VERSION "created by canmatrix"

NS_ :

BS_:

BU_: User ADM_PC_LL25 ADM_PC_BC25 ADM_PC_BP25 ADM_PC_BI25

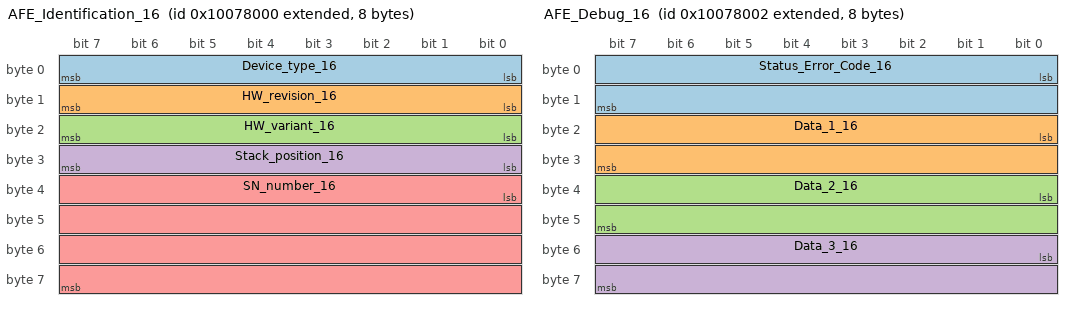
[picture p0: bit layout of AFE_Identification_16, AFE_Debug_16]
BO_ 2416410624 AFE_Identification_16: 8 ADM_PC_BP25
 SG_ Device_type_16 : 0|8@1+ (1,0) [0|255] "" Vector__XXX
 SG_ HW_revision_16 : 8|8@1+ (1,0) [0|255] "" Vector__XXX
 SG_ HW_variant_16 : 16|8@1+ (1,0) [0|255] "" Vector__XXX
 SG_ Stack_position_16 : 24|8@1+ (1,0) [0|255] "" Vector__XXX
 SG_ SN_number_16 : 32|32@1+ (1,0) [0|4294967295] "" Vector__XXX

BO_ 2416410625 AFE_FwInfo_16: 8 ADM_PC_BP25
 SG_ FW_info_mux_16 M : 56|8@1+ (1,0) [0|255] "" Vector__XXX
 SG_ FW_revision_0_16 m0 : 0|8@1+ (1,0) [0|255] "" Vector__XXX
 SG_ FW_revision_1_16 m0 : 8|8@1+ (1,0) [0|255] "" Vector__XXX
 SG_ FW_revision_2_16 m0 : 16|8@1+ (1,0) [0|255] "" Vector__XXX
 SG_ FW_revision_3_16 m0 : 24|8@1+ (1,0) [0|255] "" Vector__XXX
 SG_ FW_revision_4_16 m0 : 32|8@1+ (1,0) [0|255] "" Vector__XXX
 SG_ FW_revision_5_16 m0 : 40|8@1+ (1,0) [0|255] "" Vector__XXX
 SG_ FW_revision_6_16 m0 : 48|8@1+ (1,0) [0|255] "" Vector__XXX
 SG_ FW_revision_7_16 m1 : 0|8@1+ (1,0) [0|255] "" Vector__XXX
 SG_ FW_revision_8_16 m1 : 8|8@1+ (1,0) [0|255] "" Vector__XXX
 SG_ FW_revision_9_16 m1 : 16|8@1+ (1,0) [0|255] "" Vector__XXX
 SG_ FW_revision_10_16 m1 : 24|8@1+ (1,0) [0|255] "" Vector__XXX
 SG_ FW_revision_11_16 m1 : 32|8@1+ (1,0) [0|255] "" Vector__XXX
 SG_ FW_revision_12_16 m1 : 40|8@1+ (1,0) [0|255] "" Vector__XXX
 SG_ FW_revision_13_16 m1 : 48|8@1+ (1,0) [0|255] "" Vector__XXX
 SG_ FW_datecode_0_16 m2 : 0|8@1+ (1,0) [0|255] "" Vector__XXX
 SG_ FW_datecode_1_16 m2 : 8|8@1+ (1,0) [0|255] "" Vector__XXX
 SG_ FW_datecode_2_16 m2 : 16|8@1+ (1,0) [0|255] "" Vector__XXX
 SG_ FW_datecode_3_16 m2 : 24|8@1+ (1,0) [0|255] "" Vector__XXX
 SG_ FW_datecode_4_16 m2 : 32|8@1+ (1,0) [0|255] "" Vector__XXX
 SG_ FW_datecode_5_16 m2 : 40|8@1+ (1,0) [0|255] "" Vector__XXX
 SG_ FW_datecode_6_16 m2 : 48|8@1+ (1,0) [0|255] "" Vector__XXX
 SG_ FW_datecode_7_16 m3 : 0|8@1+ (1,0) [0|255] "" Vector__XXX
 SG_ FW_datecode_8_16 m3 : 8|8@1+ (1,0) [0|255] "" Vector__XXX
 SG_ FW_datecode_9_16 m3 : 16|8@1+ (1,0) [0|255] "" Vector__XXX
 SG_ FW_datecode_10_16 m3 : 24|8@1+ (1,0) [0|255] "" Vector__XXX
 SG_ FW_datecode_11_16 m3 : 32|8@1+ (1,0) [0|255] "" Vector__XXX
 SG_ FW_datecode_12_16 m3 : 40|8@1+ (1,0) [0|255] "" Vector__XXX
 SG_ FW_datecode_13_16 m3 : 48|8@1+ (1,0) [0|255] "" Vector__XXX

BO_ 2416410637 _AFE_Boot_FwInfo_16: 8 ADM_PC_BP25
 SG_ Boot_FW_info_mux_16 M : 56|8@1+ (1,0) [0|255] "" Vector__XXX
 SG_ FW_revision_0_16 m0 : 0|8@1+ (1,0) [0|255] "" Vector__XXX
 SG_ FW_revision_1_16 m0 : 8|8@1+ (1,0) [0|255] "" Vector__XXX
 SG_ FW_revision_2_16 m0 : 16|8@1+ (1,0) [0|255] "" Vector__XXX
 SG_ FW_revision_3_16 m0 : 24|8@1+ (1,0) [0|255] "" Vector__XXX
 SG_ FW_revision_4_16 m0 : 32|8@1+ (1,0) [0|255] "" Vector__XXX
 SG_ FW_revision_5_16 m0 : 40|8@1+ (1,0) [0|255] "" Vector__XXX
 SG_ FW_revision_6_16 m0 : 48|8@1+ (1,0) [0|255] "" Vector__XXX
 SG_ FW_revision_7_16 m1 : 0|8@1+ (1,0) [0|255] "" Vector__XXX
 SG_ FW_revision_8_16 m1 : 8|8@1+ (1,0) [0|255] "" Vector__XXX
 SG_ FW_revision_9_16 m1 : 16|8@1+ (1,0) [0|255] "" Vector__XXX
 SG_ FW_revision_10_16 m1 : 24|8@1+ (1,0) [0|255] "" Vector__XXX
 SG_ FW_revision_11_16 m1 : 32|8@1+ (1,0) [0|255] "" Vector__XXX
 SG_ FW_revision_12_16 m1 : 40|8@1+ (1,0) [0|255] "" Vector__XXX
 SG_ FW_revision_13_16 m1 : 48|8@1+ (1,0) [0|255] "" Vector__XXX
 SG_ FW_datecode_0_16 m2 : 0|8@1+ (1,0) [0|255] "" Vector__XXX
 SG_ FW_datecode_1_16 m2 : 8|8@1+ (1,0) [0|255] "" Vector__XXX
 SG_ FW_datecode_2_16 m2 : 16|8@1+ (1,0) [0|255] "" Vector__XXX
 SG_ FW_datecode_3_16 m2 : 24|8@1+ (1,0) [0|255] "" Vector__XXX
 SG_ FW_datecode_4_16 m2 : 32|8@1+ (1,0) [0|255] "" Vector__XXX
 SG_ FW_datecode_5_16 m2 : 40|8@1+ (1,0) [0|255] "" Vector__XXX
 SG_ FW_datecode_6_16 m2 : 48|8@1+ (1,0) [0|255] "" Vector__XXX
 SG_ FW_datecode_7_16 m3 : 0|8@1+ (1,0) [0|255] "" Vector__XXX
 SG_ FW_datecode_8_16 m3 : 8|8@1+ (1,0) [0|255] "" Vector__XXX
 SG_ FW_datecode_9_16 m3 : 16|8@1+ (1,0) [0|255] "" Vector__XXX
 SG_ FW_datecode_10_16 m3 : 24|8@1+ (1,0) [0|255] "" Vector__XXX
 SG_ FW_datecode_11_16 m3 : 32|8@1+ (1,0) [0|255] "" Vector__XXX
 SG_ FW_datecode_12_16 m3 : 40|8@1+ (1,0) [0|255] "" Vector__XXX
 SG_ FW_datecode_13_16 m3 : 48|8@1+ (1,0) [0|255] "" Vector__XXX

BO_ 2416410626 AFE_Debug_16: 8 ADM_PC_BP25
 SG_ Status_Error_Code_16 : 0|16@1+ (1,0) [0|65535] "" Vector__XXX
 SG_ Data_1_16 : 16|16@1+ (1,0) [0|65535] "" Vector__XXX
 SG_ Data_2_16 : 32|16@1+ (1,0) [0|65535] "" Vector__XXX
 SG_ Data_3_16 : 48|16@1+ (1,0) [0|65535] "" Vector__XXX

BO_ 2416410631 AFE_Status_16: 8 ADM_PC_BP25
 SG_ Running_16 : 0|1@1+ (1,0) [0|1] "" Vector__XXX
 SG_ PWM_16 : 1|1@1+ (1,0) [0|1] "" Vector__XXX
 SG_ Current_dc_loop_mode_16 : 2|1@1+ (1,0) [0|1] "" Vector__XXX
 SG_ Current_ac_loop_mode_16 : 3|1@1+ (1,0) [0|1] "" Vector__XXX
 SG_ Buck_16 : 5|1@1+ (1,0) [0|1] "" Vector__XXX
 SG_ Boost_16 : 6|1@1+ (1,0) [0|1] "" Vector__XXX
 SG_ Precharge_dc_buck_mode_16 : 7|1@1+ (1,0) [0|1] "" Vector__XXX
 SG_ Precharge_dc_boost_mode_16 : 8|1@1+ (1,0) [0|1] "" Vector__XXX
 SG_ Rectifier_3ph_16 : 9|1@1+ (1,0) [0|1] "" Vector__XXX
 SG_ Stack_mode_16 : 10|1@1+ (1,0) [0|1] "" Vector__XXX
 SG_ Master_16 : 11|1@1+ (1,0) [0|1] "" Vector__XXX
 SG_ Slave_16 : 12|1@1+ (1,0) [0|1] "" Vector__XXX
 SG_ Inverter_1ph_16 : 13|1@1+ (1,0) [0|1] "" Vector__XXX
 SG_ Boost_Neutral_16 : 14|1@1+ (1,0) [0|1] "" Vector__XXX
 SG_ Rectifier_1ph_16 : 15|1@1+ (1,0) [0|1] "" Vector__XXX
 SG_ Inverter_3ph_16 : 16|1@1+ (1,0) [0|1] "" Vector__XXX
 SG_ Ready_16 : 17|1@1+ (1,0) [0|1] "" Vector__XXX
 SG_ Inverter_1ph_Sync_16 : 18|1@1+ (1,0) [0|1] "" Vector__XXX
 SG_ Neutral_16 : 19|1@1+ (1,0) [0|1] "" Vector__XXX
 SG_ Rectifier_1ph_Buck_16 : 20|1@1+ (1,0) [0|1] "" Vector__XXX
 SG_ Inverter_1ph_Boost_16 : 21|1@1+ (1,0) [0|1] "" Vector__XXX
 SG_ Rectifier_distributed_16 : 22|1@1+ (1,0) [0|1] "" Vector__XXX
 SG_ MPPT_buck_16 : 23|1@1+ (1,0) [0|1] "" Vector__XXX
 SG_ MPPT_boost_16 : 24|1@1+ (1,0) [0|1] "" Vector__XXX
 SG_ Buck_2p_float_16 : 25|1@1+ (1,0) [0|1] "" Vector__XXX
 SG_ Inverter_1ph_Distributed_16 : 26|1@1+ (1,0) [0|1] "" Vector__XXX

BO_ 2416410630 AFE_Faults_16: 3 ADM_PC_BP25
 SG_ Protection_trip_internal_16 : 0|1@1+ (1,0) [0|1] "" Vector__XXX
 SG_ Protection_trip_external_16 : 1|1@1+ (1,0) [0|1] "" Vector__XXX
 SG_ Phase_U_overcurrent_16 : 2|1@1+ (1,0) [0|1] "" Vector__XXX
 SG_ Phase_U_overvoltage_16 : 3|1@1+ (1,0) [0|1] "" Vector__XXX
 SG_ Phase_U_undervoltage_16 : 4|1@1+ (1,0) [0|1] "" Vector__XXX
 SG_ Phase_V_overvoltage_16 : 5|1@1+ (1,0) [0|1] "" Vector__XXX
 SG_ Phase_V_undervoltage_16 : 6|1@1+ (1,0) [0|1] "" Vector__XXX
 SG_ Phase_V_overcurrent_16 : 7|1@1+ (1,0) [0|1] "" Vector__XXX
 SG_ Phase_W_overvoltage_16 : 8|1@1+ (1,0) [0|1] "" Vector__XXX
 SG_ Phase_W_undervoltage_16 : 9|1@1+ (1,0) [0|1] "" Vector__XXX
 SG_ Phase_W_overcurrent_16 : 10|1@1+ (1,0) [0|1] "" Vector__XXX
 SG_ DC_undervoltage_16 : 11|1@1+ (1,0) [0|1] "" Vector__XXX
 SG_ DC_overvoltage_16 : 12|1@1+ (1,0) [0|1] "" Vector__XXX
 SG_ MOSFET_overtemperature_16 : 13|1@1+ (1,0) [0|1] "" Vector__XXX
 SG_ Inductor_overtemperature_16 : 14|1@1+ (1,0) [0|1] "" Vector__XXX
 SG_ Keep_Alive_not_served_16 : 15|1@1+ (1,0) [0|1] "" Vector__XXX
 SG_ PLL_not_locked_16 : 16|1@1+ (1,0) [0|1] "" Vector__XXX
 SG_ NFO_16 : 20|1@1+ (1,0) [0|1] "" Vector__XXX
 SG_ Measurement_system_failure_16 : 21|1@1+ (1,0) [0|1] "" Vector__XXX
 SG_ EEPROM_failure_16 : 22|1@1+ (1,0) [0|1] "" Vector__XXX
 SG_ System_16 : 23|1@1+ (1,0) [0|1] "" Vector__XXX

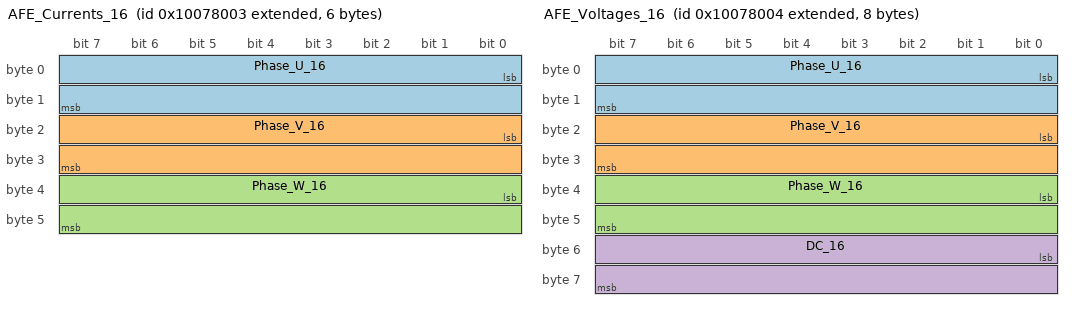
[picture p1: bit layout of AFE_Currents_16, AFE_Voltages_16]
BO_ 2416410627 AFE_Currents_16: 6 ADM_PC_BP25
 SG_ Phase_U_16 : 0|16@1- (0.01,0) [-327.68|327.67] "A" Vector__XXX
 SG_ Phase_V_16 : 16|16@1- (0.01,0) [-327.68|327.67] "A" Vector__XXX
 SG_ Phase_W_16 : 32|16@1- (0.01,0) [-327.68|327.67] "A" Vector__XXX

BO_ 2416410640 AFE_DC_Bus_current_16: 2 ADM_PC_BP25
 SG_ Bus_current_16 : 0|16@1- (0.01,0) [-327.68|327.67] "A" Vector__XXX

BO_ 2416410638 _AFE_Broadcast_16: 8 ADM_PC_BP25
 SG_ Diagnostics_Index_16 M : 56|8@1+ (1,0) [0|255] "" Vector__XXX
 SG_ Phase_U_16 m1 : 8|16@1- (0.01,0) [-327.68|327.67] "A" ADM_PC_BP25
 SG_ Phase_V_16 m1 : 24|16@1- (0.01,0) [-327.68|327.67] "A" ADM_PC_BP25
 SG_ Phase_W_16 m1 : 40|16@1- (0.01,0) [-327.68|327.67] "A" ADM_PC_BP25
 SG_ Stack_position_16 : 0|5@1+ (1,0) [0|31] "" ADM_PC_BP25
 SG_ Group_ID_16 : 5|3@1+ (1,0) [0|7] "" ADM_PC_BP25

BO_ 2416410628 AFE_Voltages_16: 8 ADM_PC_BP25
 SG_ Phase_U_16 : 0|16@1- (0.1,0) [-3276.8|3276.7] "V" Vector__XXX
 SG_ Phase_V_16 : 16|16@1- (0.1,0) [-3276.8|3276.7] "V" Vector__XXX
 SG_ Phase_W_16 : 32|16@1- (0.1,0) [-3276.8|3276.7] "V" Vector__XXX
 SG_ DC_16 : 48|16@1- (0.1,0) [-3276.8|3276.7] "V" Vector__XXX

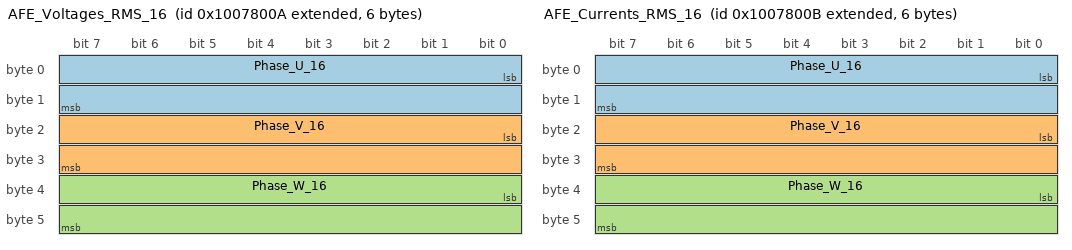
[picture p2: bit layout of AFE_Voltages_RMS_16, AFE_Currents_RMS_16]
BO_ 2416410634 AFE_Voltages_RMS_16: 6 ADM_PC_BP25
 SG_ Phase_U_16 : 0|16@1+ (0.1,0) [0|6553.5] "V" Vector__XXX
 SG_ Phase_V_16 : 16|16@1+ (0.1,0) [0|6553.5] "V" Vector__XXX
 SG_ Phase_W_16 : 32|16@1+ (0.1,0) [0|6553.5] "V" Vector__XXX

BO_ 2416410635 AFE_Currents_RMS_16: 6 ADM_PC_BP25
 SG_ Phase_U_16 : 0|16@1+ (0.01,0) [0.00|655.35] "A" Vector__XXX
 SG_ Phase_V_16 : 16|16@1+ (0.01,0) [0.00|655.35] "A" Vector__XXX
 SG_ Phase_W_16 : 32|16@1+ (0.01,0) [0.00|655.35] "A" Vector__XXX

BO_ 2416410636 AFE_Mains_16: 4 ADM_PC_BP25
 SG_ Frequency_16 : 0|16@1+ (0.01,0) [0.00|655.35] "Hz" Vector__XXX
 SG_ Phase_16 : 16|16@1- (0.1,0) [-3276.8|3276.7] "Deg." Vector__XXX

BO_ 2416410629 AFE_Temperatures_16: 4 ADM_PC_BP25
 SG_ Temp_Bridge_16 : 0|16@1- (0.01,0) [-327.68|327.67] "°C" Vector__XXX
 SG_ Temp_Inductors_16 : 16|16@1- (0.01,0) [-327.68|327.67] "°C" Vector__XXX

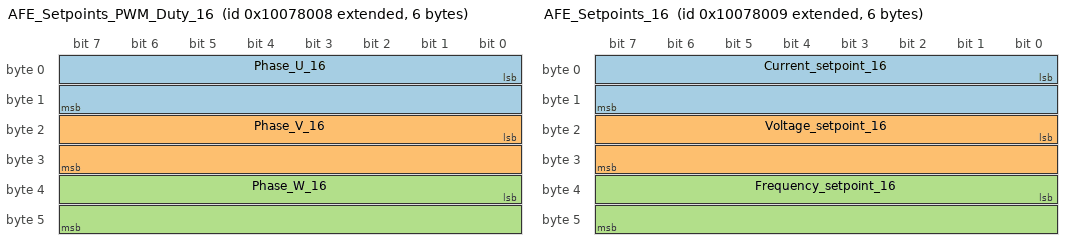
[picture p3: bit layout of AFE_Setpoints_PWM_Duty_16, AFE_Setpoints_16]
BO_ 2416410632 AFE_Setpoints_PWM_Duty_16: 6 ADM_PC_BP25
 SG_ Phase_U_16 : 0|16@1+ (0.001525902,0) [0E-009|99.999987570] "%" Vector__XXX
 SG_ Phase_V_16 : 16|16@1+ (0.001525902,0) [0E-009|99.999987570] "%" Vector__XXX
 SG_ Phase_W_16 : 32|16@1+ (0.001525902,0) [0E-009|99.999987570] "%" Vector__XXX

BO_ 2416410633 AFE_Setpoints_16: 6 ADM_PC_BP25
 SG_ Current_setpoint_16 : 0|16@1- (0.01,0) [-327.68|327.67] "A" Vector__XXX
 SG_ Voltage_setpoint_16 : 16|16@1+ (0.1,0) [0|6553.5] "V" Vector__XXX
 SG_ Frequency_setpoint_16 : 32|16@1+ (0.01,0) [0.00|655.35] "Hz" Vector__XXX

BO_ 2416377952 AFE_Keep_Alive_16: 1 User
 SG_ Keep_Alive_Enable_16 : 0|1@1+ (1,0) [0|1] "" ADM_PC_BP25

BO_ 2416377920 AFE_Mode_Control_16: 8 User
 SG_ Converter_ON_16 : 0|1@1+ (1,0) [0|1] "" ADM_PC_BP25
 SG_ PWM_ON_16 : 1|1@1+ (1,0) [0|1] "" ADM_PC_BP25
 SG_ DC_Current_feedback_ON_16 : 2|1@1+ (1,0) [0|1] "" ADM_PC_BP25
 SG_ AC_Current_feedback_ON_16 : 3|1@1+ (1,0) [0|1] "" ADM_PC_BP25
 SG_ Buck_ON_16 : 5|1@1+ (1,0) [0|1] "" ADM_PC_BP25
 SG_ Boost_ON_16 : 6|1@1+ (1,0) [0|1] "" ADM_PC_BP25
 SG_ Rectifier_3ph_ON_16 : 9|1@1+ (1,0) [0|1] "" ADM_PC_BP25
 SG_ Inverter_1ph_ON_16 : 10|1@1+ (1,0) [0|1] "" ADM_PC_BP25
 SG_ Rectifier_1ph_ON_16 : 11|1@1+ (1,0) [0|1] "" ADM_PC_BP25
 SG_ Boost_Neutral_ON_16 : 12|1@1+ (1,0) [0|1] "" ADM_PC_BP25
 SG_ Inverter_3ph_ON_16 : 13|1@1+ (1,0) [0|1] "" ADM_PC_BP25
 SG_ Inverter_1ph_Sync_ON_16 : 14|1@1+ (1,0) [0|1] "" ADM_PC_BP25
 SG_ Neutral_ON_16 : 15|1@1+ (1,0) [0|1] "" ADM_PC_BP25
 SG_ Rectifier_1ph_Buck_ON_16 : 16|1@1+ (1,0) [0|1] "" ADM_PC_BP25
 SG_ Inverter_1ph_Boost_ON_16 : 17|1@1+ (1,0) [0|1] "" ADM_PC_BP25
 SG_ Rectifier_Distributed_ON_16 : 18|1@1+ (1,0) [0|1] "" ADM_PC_BP25
 SG_ MPPT_buck_ON_16 : 19|1@1+ (1,0) [0|1] "" ADM_PC_BP25
 SG_ MPPT_boost_ON_16 : 20|1@1+ (1,0) [0|1] "" ADM_PC_BP25
 SG_ Buck_2p_float_ON_16 : 21|1@1+ (1,0) [0|1] "" ADM_PC_BP25
 SG_ Inverter_1ph_Distributed_ON_16 : 22|1@1+ (1,0) [0|1] "" ADM_PC_BP25

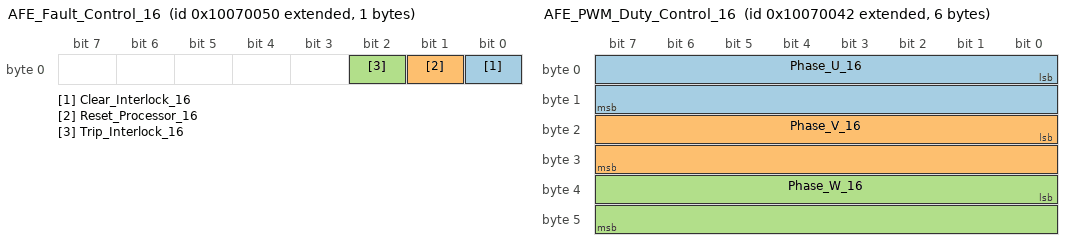
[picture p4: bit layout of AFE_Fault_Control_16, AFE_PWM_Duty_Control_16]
BO_ 2416377936 AFE_Fault_Control_16: 1 User
 SG_ Clear_Interlock_16 : 0|1@1+ (1,0) [0|1] "" ADM_PC_BP25
 SG_ Reset_Processor_16 : 1|1@1+ (1,0) [0|1] "" ADM_PC_BP25
 SG_ Trip_Interlock_16 : 2|1@1+ (1,0) [0|1] "" ADM_PC_BP25

BO_ 2416377921 AFE_Reactive_Current_Setpoint_Co: 2 User
 SG_ Reactive_current_setpoint_16 : 0|16@1- (0.01,0) [-150|150] "A" ADM_PC_BP25

BO_ 2416377922 AFE_PWM_Duty_Control_16: 6 User
 SG_ Phase_U_16 : 0|16@1+ (0.001525902,0) [0E-009|99.999987570] "%" ADM_PC_BP25
 SG_ Phase_V_16 : 16|16@1+ (0.001525902,0) [0E-009|99.999987570] "%" ADM_PC_BP25
 SG_ Phase_W_16 : 32|16@1+ (0.001525902,0) [0E-009|99.999987570] "%" ADM_PC_BP25

BO_ 2416377923 AFE_Current_Setpoint_Control_16: 2 User
 SG_ Current_setpoint_16 : 0|16@1- (0.01,0) [-150|150] "A" ADM_PC_BP25

BO_ 2416377924 AFE_Voltage_Setpoint_Control_16: 2 User
 SG_ Voltage_setpoint_16 : 0|16@1+ (0.1,0) [0|1500] "V" ADM_PC_BP25

BO_ 2416377928 AFE_Frequency_Setpoint_Control_1: 2 User
 SG_ Frequency_setpoint_16 : 0|16@1+ (0.01,0) [40|70] "Hz" ADM_PC_BP25

BO_ 2416377929 AFE_Phase_Setpoint_Control_16: 2 User
 SG_ Phase_setpoint_16 : 0|16@1+ (1,0) [0|360] "deg" ADM_PC_BP25

BO_ 2416377968 AFE_Rectifier_Setpoint_Control_1: 8 User
 SG_ Voltage_setpoint_2_16 : 0|16@1+ (0.1,0) [0|1500] "V" ADM_PC_BP25
 SG_ Current_setpoint_2_16 : 16|16@1- (0.01,0) [-150|150] "A" ADM_PC_BP25

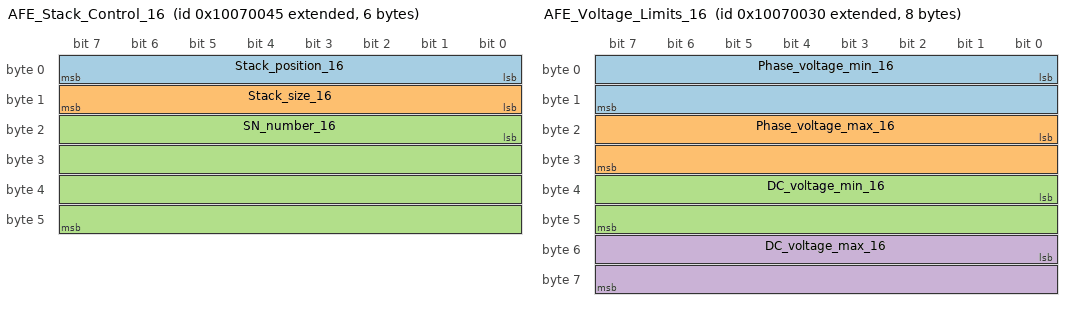
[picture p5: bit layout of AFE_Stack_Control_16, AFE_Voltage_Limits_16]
BO_ 2416377925 AFE_Stack_Control_16: 6 User
 SG_ Stack_position_16 : 0|8@1+ (1,0) [0|255] "" ADM_PC_BP25
 SG_ Stack_size_16 : 8|8@1+ (1,0) [0|255] "" ADM_PC_BP25
 SG_ SN_number_16 : 16|32@1+ (1,0) [0|4294967295] "" ADM_PC_BP25

BO_ 2416377904 AFE_Voltage_Limits_16: 8 User
 SG_ Phase_voltage_min_16 : 0|16@1- (0.1,0) [0|3276.7] "V" ADM_PC_BP25
 SG_ Phase_voltage_max_16 : 16|16@1- (0.1,0) [-3276.8|850] "V" ADM_PC_BP25
 SG_ DC_voltage_min_16 : 32|16@1- (0.1,0) [0|3276.7] "V" ADM_PC_BP25
 SG_ DC_voltage_max_16 : 48|16@1- (0.1,0) [-3276.8|850] "V" ADM_PC_BP25

BO_ 2416377905 AFE_Current_Limits_16: 4 User
 SG_ Phase_current_min_16 : 0|16@1- (0.01,0) [-60|60] "A" ADM_PC_BP25
 SG_ Phase_current_max_16 : 16|16@1- (0.01,0) [-60|60] "A" ADM_PC_BP25

BO_ 2416377932 AFE_Group_Control_16: 1 User
 SG_ Group_ID_16 : 0|8@1+ (1,0) [0|255] "" ADM_PC_BP25

BO_ 2416410639 AFE_Group_Info_16: 1 ADM_PC_BP25
 SG_ Group_ID_16 : 0|8@1+ (1,0) [0|255] "" Vector__XXX

BO_ 2416377953 AFE_System_Flags_Control_16: 8 User
 SG_ Factory_mode_16 : 0|1@1+ (1,0) [0|1] "" ADM_PC_BP25
 SG_ Silent_CAN_mode_16 : 1|1@1+ (1,0) [0|1] "" ADM_PC_BP25

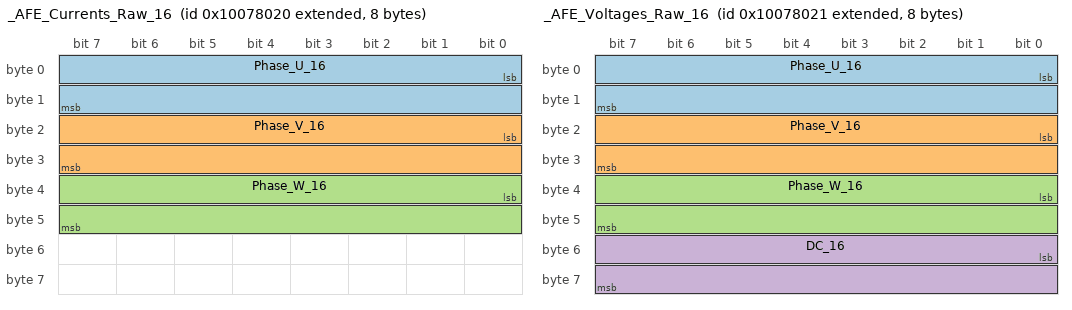
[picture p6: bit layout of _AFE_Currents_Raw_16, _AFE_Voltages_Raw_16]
BO_ 2416410656 _AFE_Currents_Raw_16: 8 ADM_PC_BP25
 SG_ Phase_U_16 : 0|16@1- (1,0) [-32768|32767] "" Vector__XXX
 SG_ Phase_V_16 : 16|16@1- (1,0) [-32768|32767] "" Vector__XXX
 SG_ Phase_W_16 : 32|16@1- (1,0) [-32768|32767] "" Vector__XXX

BO_ 2416410657 _AFE_Voltages_Raw_16: 8 ADM_PC_BP25
 SG_ Phase_U_16 : 0|16@1- (1,0) [-32768|32767] "" Vector__XXX
 SG_ Phase_V_16 : 16|16@1- (1,0) [-32768|32767] "" Vector__XXX
 SG_ Phase_W_16 : 32|16@1- (1,0) [-32768|32767] "" Vector__XXX
 SG_ DC_16 : 48|16@1- (1,0) [-32768|32767] "" Vector__XXX

BO_ 2416377930 _AFE_ADC_Calibration_Mode_16: 1 User
 SG_ Calibration_Index_16 M : 2|5@1+ (1,0) [0|31] "" Vector__XXX
 SG_ Current_U_16 m1 : 0|2@1+ (1,0) [0|3] "" ADM_PC_BP25
 SG_ Current_V_16 m2 : 0|2@1+ (1,0) [0|3] "" ADM_PC_BP25
 SG_ Current_W_16 m3 : 0|2@1+ (1,0) [0|3] "" ADM_PC_BP25
 SG_ Voltage_U_16 m4 : 0|2@1+ (1,0) [0|3] "" ADM_PC_BP25
 SG_ Voltage_V_16 m5 : 0|2@1+ (1,0) [0|3] "" ADM_PC_BP25
 SG_ Voltage_W_16 m6 : 0|2@1+ (1,0) [0|3] "" ADM_PC_BP25
 SG_ Voltage_DC_16 m7 : 0|2@1+ (1,0) [0|3] "" ADM_PC_BP25
 SG_ start_16 : 7|1@1+ (1,0) [0|1] "" ADM_PC_BP25

BO_ 2416377931 _AFE_ADC_Calibration_Setpoint_16: 3 User
 SG_ Calibration_Index_16 M : 16|5@1+ (1,0) [0|31] "" Vector__XXX
 SG_ Current_U_16 m1 : 0|16@1- (0.01,0) [-100|100] "A" ADM_PC_BP25
 SG_ Current_V_16 m2 : 0|16@1- (0.01,0) [-100|100] "A" ADM_PC_BP25
 SG_ Current_W_16 m3 : 0|16@1- (0.01,0) [-100|100] "A" ADM_PC_BP25
 SG_ Voltage_U_16 m4 : 0|16@1+ (0.1,0) [0|1500] "V" ADM_PC_BP25
 SG_ Voltage_V_16 m5 : 0|16@1+ (0.1,0) [0|1500] "V" ADM_PC_BP25
 SG_ Voltage_W_16 m6 : 0|16@1+ (0.1,0) [0|1500] "V" ADM_PC_BP25
 SG_ Voltage_DC_16 m7 : 0|16@1+ (0.1,0) [0|1500] "V" ADM_PC_BP25
 SG_ point_16 : 21|3@1+ (1,0) [0|7] "" ADM_PC_BP25

BO_ 2416377926 _AFE_Calibration_Offset_Update_1: 6 User
 SG_ Calibration_Index_16 M : 16|16@1+ (1,0) [0|65535] "" Vector__XXX
 SG_ Current_U_16 m0 : 0|16@1- (1,0) [-32768|32767] "ADC Counts" ADM_PC_BP25
 SG_ Current_V_16 m1 : 0|16@1- (1,0) [-32768|32767] "ADC Counts" ADM_PC_BP25
 SG_ Current_W_16 m2 : 0|16@1- (1,0) [-32768|32767] "ADC Counts" ADM_PC_BP25
 SG_ Voltage_U_16 m3 : 0|16@1- (1,0) [-32768|32767] "ADC Counts" ADM_PC_BP25
 SG_ Voltage_V_16 m4 : 0|16@1- (1,0) [-32768|32767] "ADC Counts" ADM_PC_BP25
 SG_ Voltage_W_16 m5 : 0|16@1- (1,0) [-32768|32767] "ADC Counts" ADM_PC_BP25
 SG_ Voltage_DC_16 m6 : 0|16@1- (1,0) [-32768|32767] "ADC Counts" ADM_PC_BP25
 SG_ CRC_16 : 32|16@1+ (1,0) [0|65535] "-" ADM_PC_BP25

BO_ 2416377927 _AFE_Calibration_Scale_Update_16: 6 User
 SG_ Calibration_Index_16 M : 16|16@1+ (1,0) [0|65535] "" Vector__XXX
 SG_ Current_U_16 m0 : 0|16@1- (0.0000152587890625,0) [-0.5000000000000000|0.4999847412109375] "scale = 1.0 + value" ADM_PC_BP25
 SG_ Current_V_16 m1 : 0|16@1- (0.0000152587890625,0) [-0.5000000000000000|0.4999847412109375] "scale = 1.0 + value" ADM_PC_BP25
 SG_ Current_W_16 m2 : 0|16@1- (0.0000152587890625,0) [-0.5000000000000000|0.4999847412109375] "scale = 1.0 + value" ADM_PC_BP25
 SG_ Voltage_U_16 m3 : 0|16@1- (0.0000152587890625,0) [-0.5000000000000000|0.4999847412109375] "scale = 1.0 + value" ADM_PC_BP25
 SG_ Voltage_V_16 m4 : 0|16@1- (0.0000152587890625,0) [-0.5000000000000000|0.4999847412109375] "scale = 1.0 + value" ADM_PC_BP25
 SG_ Voltage_W_16 m5 : 0|16@1- (0.0000152587890625,0) [-0.5000000000000000|0.4999847412109375] "scale = 1.0 + value" ADM_PC_BP25
 SG_ Voltage_DC_16 m6 : 0|16@1- (0.0000152587890625,0) [-0.5000000000000000|0.4999847412109375] "scale = 1.0 + value" ADM_PC_BP25
 SG_ CRC_16 : 32|16@1+ (1,0) [0|65535] "-" ADM_PC_BP25

BO_ 2416410705 _AFE_Calibration_Adc_Scale_16: 6 ADM_PC_BP25
 SG_ Adc_Index_16 M : 32|16@1+ (1,0) [0|65535] "" Vector__XXX
 SG_ Current_U_16 m0 : 0|32@1+ (1,0) [0|4294967295] "1 / adc_bins" User
 SG_ Current_V_16 m1 : 0|32@1+ (1,0) [0|4294967295] "1 / adc_bins" User
 SG_ Current_W_16 m2 : 0|32@1+ (1,0) [0|4294967295] "1 / adc_bins" User
 SG_ Voltage_U_16 m3 : 0|32@1+ (1,0) [0|4294967295] "1 / adc_bins" User
 SG_ Voltage_V_16 m4 : 0|32@1+ (1,0) [0|4294967295] "1 / adc_bins" User
 SG_ Voltage_W_16 m5 : 0|32@1+ (1,0) [0|4294967295] "1 / adc_bins" User
 SG_ Voltage_DC_16 m6 : 0|32@1+ (1,0) [0|4294967295] "1 / adc_bins" User

BO_ 2416410706 _AFE_Calibration_Adc_Fs_16: 6 ADM_PC_BP25
 SG_ Adc_Index_16 M : 32|16@1+ (1,0) [0|65535] "" Vector__XXX
 SG_ Current_U_16 m0 : 0|32@1+ (1,0) [0|4294967295] "Fullscale" User
 SG_ Current_V_16 m1 : 0|32@1+ (1,0) [0|4294967295] "Fullscale" User
 SG_ Current_W_16 m2 : 0|32@1+ (1,0) [0|4294967295] "Fullscale" User
 SG_ Voltage_U_16 m3 : 0|32@1+ (1,0) [0|4294967295] "Fullscale" User
 SG_ Voltage_V_16 m4 : 0|32@1+ (1,0) [0|4294967295] "Fullscale" User
 SG_ Voltage_W_16 m5 : 0|32@1+ (1,0) [0|4294967295] "Fullscale" User
 SG_ Voltage_DC_16 m6 : 0|32@1+ (1,0) [0|4294967295] "Fullscale" User

BO_ 2416410707 _AFE_Calibration_Adc_Offset_16: 4 ADM_PC_BP25
 SG_ Adc_Index_16 M : 16|16@1+ (1,0) [0|65535] "" Vector__XXX
 SG_ Current_U_16 m0 : 0|16@1- (1,0) [-32768|32767] "-" User
 SG_ Current_V_16 m1 : 0|16@1- (1,0) [-32768|32767] "-" User
 SG_ Current_W_16 m2 : 0|16@1- (1,0) [-32768|32767] "-" User
 SG_ Voltage_U_16 m3 : 0|16@1- (1,0) [-32768|32767] "-" User
 SG_ Voltage_V_16 m4 : 0|16@1- (1,0) [-32768|32767] "-" User
 SG_ Voltage_W_16 m5 : 0|16@1- (1,0) [-32768|32767] "-" User
 SG_ Voltage_DC_16 m6 : 0|16@1- (1,0) [-32768|32767] "-" User

BO_ 2416410708 _AFE_Calibration_Adc_Gain_16: 4 ADM_PC_BP25
 SG_ Adc_Index_16 M : 16|16@1+ (1,0) [0|65535] "" Vector__XXX
 SG_ Current_U_16 m0 : 0|16@1- (1,0) [-32768|32767] "-" User
 SG_ Current_V_16 m1 : 0|16@1- (1,0) [-32768|32767] "-" User
 SG_ Current_W_16 m2 : 0|16@1- (1,0) [-32768|32767] "-" User
 SG_ Voltage_U_16 m3 : 0|16@1- (1,0) [-32768|32767] "-" User
 SG_ Voltage_V_16 m4 : 0|16@1- (1,0) [-32768|32767] "-" User
 SG_ Voltage_W_16 m5 : 0|16@1- (1,0) [-32768|32767] "-" User
 SG_ Voltage_DC_16 m6 : 0|16@1- (1,0) [-32768|32767] "-" User

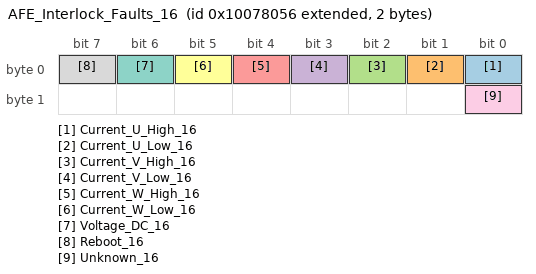
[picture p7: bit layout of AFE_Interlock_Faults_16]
BO_ 2416410710 AFE_Interlock_Faults_16: 2 ADM_PC_BP25
 SG_ Current_U_High_16 : 0|1@1+ (1,0) [0|1] "" Vector__XXX
 SG_ Current_U_Low_16 : 1|1@1+ (1,0) [0|1] "" Vector__XXX
 SG_ Current_V_High_16 : 2|1@1+ (1,0) [0|1] "" Vector__XXX
 SG_ Current_V_Low_16 : 3|1@1+ (1,0) [0|1] "" Vector__XXX
 SG_ Current_W_High_16 : 4|1@1+ (1,0) [0|1] "" Vector__XXX
 SG_ Current_W_Low_16 : 5|1@1+ (1,0) [0|1] "" Vector__XXX
 SG_ Voltage_DC_16 : 6|1@1+ (1,0) [0|1] "" Vector__XXX
 SG_ Reboot_16 : 7|1@1+ (1,0) [0|1] "" Vector__XXX
 SG_ Unknown_16 : 8|1@1+ (1,0) [0|1] "" Vector__XXX

BO_TX_BU_ 2416377920 : User,ADM_PC_LL25,ADM_PC_BC25,ADM_PC_BI25;
BO_TX_BU_ 2416377923 : User,ADM_PC_LL25,ADM_PC_BC25,ADM_PC_BI25;
BO_TX_BU_ 2416377924 : User,ADM_PC_LL25,ADM_PC_BC25,ADM_PC_BI25;
CM_ BO_ 2416410624  "Identification of the device";
CM_ BO_ 2416410625  "Git revision of the DSP firmware";
CM_ BO_ 2416410637  "Git revision of the bootloader firmware.";
CM_ BO_ 2416410626  "Values for debugging of HW/SW problems";
CM_ BO_ 2416410631  "Status bitfield";
CM_ BO_ 2416410630  "Fault bitfield";
CM_ BO_ 2416410627  "Current of phases U, V, W";
CM_ BO_ 2416410640  "Current of of the DC Bus";
CM_ BO_ 2416410638  "All AFEs will listen to this message";
CM_ BO_ 2416410635  "RMS Current of phases U, V, W";
CM_ BO_ 2416410636  "Three-Phase mains health (frequency, phase...)";
CM_ BO_ 2416410629  "Readouts of the module temperature sensors";
CM_ BO_ 2416410632  "Setpoints";
CM_ BO_ 2416410633  "Setpoints";
CM_ BO_ 2416377952  "Keep alive ping message. ";
CM_ BO_ 2416377920  "Operation Mode control: sets the converter operation mode";
CM_ BO_ 2416377936  "Fault Control: actions to clear faults and reset the system";
CM_ BO_ 2416377921  "Reactive power setpoint control.";
CM_ BO_ 2416377922  "PWM duty cycle control";
CM_ BO_ 2416377923  "Current setpoint control";
CM_ BO_ 2416377924  "Voltage setpoint control";
CM_ BO_ 2416377928  "Frequency setpoint control";
CM_ BO_ 2416377929  "Phase setpoint control";
CM_ BO_ 2416377968  "Additional voltage and current setpoints in single-phase rectifier and inverter control modes.";
CM_ BO_ 2416377925  "PFC stack control";
CM_ BO_ 2416377904  "Set the input and output voltage limits (minimum and maximum)";
CM_ BO_ 2416377905  "Set the output current limits (mminimum and maximum)";
CM_ BO_ 2416377932  "Set the Group ID of the device";
CM_ BO_ 2416410639  "Contains the Group ID of the device";
CM_ BO_ 2416377953  "Control the system flags";
CM_ BO_ 2416410656  "Current of phases A and B";
CM_ BO_ 2416410657  "Current of phases A and B";
CM_ BO_ 2416377930  "Automatic ADC calibration.";
CM_ BO_ 2416377931  "Setpoint for automatic ADC calibration.";
CM_ BO_ 2416377926  "Update of the calibration table for offsets.";
CM_ BO_ 2416377927  "Update of the calibration table for scales.";
CM_ BO_ 2416410705  "
                Adc scale (resolution) value of readouts.
            ";
CM_ BO_ 2416410706  "
                Adc fullscale value of readouts.
            ";
CM_ BO_ 2416410707  "
                Readout of ADC calibration data (offset) from EEPROM.
            ";
CM_ BO_ 2416410708  "
                Readout of ADC calibration data (gain) from EEPROM.
            ";
CM_ BO_ 2416410710  "Fault bitfield";

CM_ SG_ 2416410624 Device_type_16 "The device identification field, uniquely identifies the sender in the network";
CM_ SG_ 2416410624 HW_revision_16 "The hardware revision number";
CM_ SG_ 2416410624 HW_variant_16 "The DSP firmware revision number";
CM_ SG_ 2416410624 Stack_position_16 "Position of the module within the stack";
CM_ SG_ 2416410624 SN_number_16 "Unique module serial number";
CM_ SG_ 2416410625 FW_revision_0_16 "Character 0";
CM_ SG_ 2416410625 FW_revision_1_16 "Character 1";
CM_ SG_ 2416410625 FW_revision_2_16 "Character 2";
CM_ SG_ 2416410625 FW_revision_3_16 "Character 3";
CM_ SG_ 2416410625 FW_revision_4_16 "Character 3";
CM_ SG_ 2416410625 FW_revision_5_16 "Character 3";
CM_ SG_ 2416410625 FW_revision_6_16 "Character 3";
CM_ SG_ 2416410625 FW_revision_7_16 "Character 7";
CM_ SG_ 2416410625 FW_revision_8_16 "Character 8";
CM_ SG_ 2416410625 FW_revision_9_16 "Character 9";
CM_ SG_ 2416410625 FW_revision_10_16 "Character 10";
CM_ SG_ 2416410625 FW_revision_11_16 "Character 11";
CM_ SG_ 2416410625 FW_revision_12_16 "Character 12";
CM_ SG_ 2416410625 FW_revision_13_16 "Character 13";
CM_ SG_ 2416410625 FW_datecode_0_16 "Character 0";
CM_ SG_ 2416410625 FW_datecode_1_16 "Character 1";
CM_ SG_ 2416410625 FW_datecode_2_16 "Character 2";
CM_ SG_ 2416410625 FW_datecode_3_16 "Character 3";
CM_ SG_ 2416410625 FW_datecode_4_16 "Character 3";
CM_ SG_ 2416410625 FW_datecode_5_16 "Character 3";
CM_ SG_ 2416410625 FW_datecode_6_16 "Character 3";
CM_ SG_ 2416410625 FW_datecode_7_16 "Character 7";
CM_ SG_ 2416410625 FW_datecode_8_16 "Character 8";
CM_ SG_ 2416410625 FW_datecode_9_16 "Character 9";
CM_ SG_ 2416410625 FW_datecode_10_16 "Character 10";
CM_ SG_ 2416410625 FW_datecode_11_16 "Character 11";
CM_ SG_ 2416410625 FW_datecode_12_16 "Character 12";
CM_ SG_ 2416410625 FW_datecode_13_16 "Character 13";
CM_ SG_ 2416410637 FW_revision_0_16 "Character 0";
CM_ SG_ 2416410637 FW_revision_1_16 "Character 1";
CM_ SG_ 2416410637 FW_revision_2_16 "Character 2";
CM_ SG_ 2416410637 FW_revision_3_16 "Character 3";
CM_ SG_ 2416410637 FW_revision_4_16 "Character 3";
CM_ SG_ 2416410637 FW_revision_5_16 "Character 3";
CM_ SG_ 2416410637 FW_revision_6_16 "Character 3";
CM_ SG_ 2416410637 FW_revision_7_16 "Character 7";
CM_ SG_ 2416410637 FW_revision_8_16 "Character 8";
CM_ SG_ 2416410637 FW_revision_9_16 "Character 9";
CM_ SG_ 2416410637 FW_revision_10_16 "Character 10";
CM_ SG_ 2416410637 FW_revision_11_16 "Character 11";
CM_ SG_ 2416410637 FW_revision_12_16 "Character 12";
CM_ SG_ 2416410637 FW_revision_13_16 "Character 13";
CM_ SG_ 2416410637 FW_datecode_0_16 "Character 0";
CM_ SG_ 2416410637 FW_datecode_1_16 "Character 1";
CM_ SG_ 2416410637 FW_datecode_2_16 "Character 2";
CM_ SG_ 2416410637 FW_datecode_3_16 "Character 3";
CM_ SG_ 2416410637 FW_datecode_4_16 "Character 3";
CM_ SG_ 2416410637 FW_datecode_5_16 "Character 3";
CM_ SG_ 2416410637 FW_datecode_6_16 "Character 3";
CM_ SG_ 2416410637 FW_datecode_7_16 "Character 7";
CM_ SG_ 2416410637 FW_datecode_8_16 "Character 8";
CM_ SG_ 2416410637 FW_datecode_9_16 "Character 9";
CM_ SG_ 2416410637 FW_datecode_10_16 "Character 10";
CM_ SG_ 2416410637 FW_datecode_11_16 "Character 11";
CM_ SG_ 2416410637 FW_datecode_12_16 "Character 12";
CM_ SG_ 2416410637 FW_datecode_13_16 "Character 13";
CM_ SG_ 2416410626 Status_Error_Code_16 "Main status / error code as defined in errno/errno.h";
CM_ SG_ 2416410626 Data_1_16 "Additional information for the error/status";
CM_ SG_ 2416410626 Data_2_16 "Additional information for the error/status";
CM_ SG_ 2416410626 Data_3_16 "Additional information for the error/status";
CM_ SG_ 2416410631 Running_16 "Indicates if converter is running.";
CM_ SG_ 2416410631 PWM_16 "Indicates if converter is in PWM control mode.";
CM_ SG_ 2416410631 Current_dc_loop_mode_16 "Indicates if the current DC loop is enabled.";
CM_ SG_ 2416410631 Current_ac_loop_mode_16 "Indicates if the current AC loop is enabled.";
CM_ SG_ 2416410631 Buck_16 "Indicates if converter is in buck control mode.";
CM_ SG_ 2416410631 Boost_16 "Indicates if converter is in boost control mode.";
CM_ SG_ 2416410631 Precharge_dc_buck_mode_16 "Indicates if the precharge DC mode is enabled - buck direction.";
CM_ SG_ 2416410631 Precharge_dc_boost_mode_16 "Indicates if the precharge DC mode is enabled - boost direction.";
CM_ SG_ 2416410631 Rectifier_3ph_16 "Indicates if converter is in three-phase rectifier control mode.";
CM_ SG_ 2416410631 Stack_mode_16 "Indicates if converter is operating in stack mode.";
CM_ SG_ 2416410631 Master_16 "Indicates if converter is master in the stack.";
CM_ SG_ 2416410631 Slave_16 "Indicates if converter is slave in the stack.";
CM_ SG_ 2416410631 Inverter_1ph_16 "Indicates if converter is in single-phase inverter control mode.";
CM_ SG_ 2416410631 Boost_Neutral_16 "Indicates if converter is in boost control mode with neutral generation.";
CM_ SG_ 2416410631 Rectifier_1ph_16 "Indicates if converter is in single-phase rectifier control mode.";
CM_ SG_ 2416410631 Inverter_3ph_16 "Indicates if converter is in three-phase inverter control mode.";
CM_ SG_ 2416410631 Ready_16 "Indicates if converter is ready for operation.";
CM_ SG_ 2416410631 Inverter_1ph_Sync_16 "Single-phase inverter control mode with phase synchronization.";
CM_ SG_ 2416410631 Neutral_16 "Open-loop neutral generation.";
CM_ SG_ 2416410631 Rectifier_1ph_Buck_16 "Single-phase rectifier with buck on one leg.";
CM_ SG_ 2416410631 Inverter_1ph_Boost_16 "Single-phase inverter with boost on one leg.";
CM_ SG_ 2416410631 Rectifier_distributed_16 "Not available at the moment";
CM_ SG_ 2416410631 MPPT_buck_16 "Not available at the moment";
CM_ SG_ 2416410631 MPPT_boost_16 "Not available at the moment";
CM_ SG_ 2416410631 Buck_2p_float_16 "Buck in phases L1 and L2. Phase L3 is left floating (high impedance)";
CM_ SG_ 2416410631 Inverter_1ph_Distributed_16 "Single-phase inverter mode  distributed";
CM_ SG_ 2416410630 Protection_trip_internal_16 "This flagg is asserted if the interlock is open due to an internal fault condition (self-protection)";
CM_ SG_ 2416410630 Protection_trip_external_16 "This flag is asserted if the interlock is open due to an external condition received in the module.";
CM_ SG_ 2416410630 Phase_U_overcurrent_16 "Indicates an overcurrent event on Phase U. The overcurrent event is triggered when the measured phase current is over the programmed current limit.";
CM_ SG_ 2416410630 Phase_U_overvoltage_16 "Indicates an overvoltage event on Phase U. The overvoltage event is triggered when the measured phase voltage is over the programmed voltage limit.";
CM_ SG_ 2416410630 Phase_U_undervoltage_16 "Indicates an undervoltage event on Phase U. The overvoltage event is triggered when the measured phase voltage is over the programmed voltage limit.";
CM_ SG_ 2416410630 Phase_V_overvoltage_16 "Indicates an overvoltage event on Phase V. The overvoltage event is triggered when the measured phase voltage is over the programmed voltage limit.";
CM_ SG_ 2416410630 Phase_V_undervoltage_16 "Indicates an undervoltage event on Phase U. The overvoltage event is triggered when the measured phase voltage is over the programmed voltage limit.";
CM_ SG_ 2416410630 Phase_V_overcurrent_16 "Indicates an overcurrent event on Phase U. The overcurrent event is triggered when the measured phase current is over the programmed current limit.";
CM_ SG_ 2416410630 Phase_W_overvoltage_16 "Indicates an overvoltage event on Phase U. The overvoltage event is triggered when the measured phase voltage is over the programmed voltage limit.";
CM_ SG_ 2416410630 Phase_W_undervoltage_16 "Indicates an undervoltage event on Phase U. The overvoltage event is triggered when the measured phase voltage is over the programmed voltage limit.";
CM_ SG_ 2416410630 Phase_W_overcurrent_16 "Indicates an overcurrent event on Phase U. The overcurrent event is triggered when the measured phase current is over the programmed current limit.";
CM_ SG_ 2416410630 DC_undervoltage_16 "DC bus undervoltage condition. The undervoltage condition is asserted when the measured dc bus voltage is under the programmed voltage limit.";
CM_ SG_ 2416410630 DC_overvoltage_16 "DC bus overvoltage condition. The overvoltage condition is asserted when the measured dc bus voltage is over the programmed voltage limit.";
CM_ SG_ 2416410630 MOSFET_overtemperature_16 "This flag is asserted when the temperature of the MOSFET block is too high.";
CM_ SG_ 2416410630 Inductor_overtemperature_16 "This flag is asserted when the temperature of the inductor block is too high.";
CM_ SG_ 2416410630 Keep_Alive_not_served_16 "The Keep Alive feature is enabled but it was not served with the periodic message.";
CM_ SG_ 2416410630 PLL_not_locked_16 "Flag asserted when in rectifier modes, the PLL went out of lock condition";
CM_ SG_ 2416410630 Measurement_system_failure_16 "The voltages/currents measurement system is malfunctionning, and readouts are not guaranteed to be accurate.";
CM_ SG_ 2416410630 EEPROM_failure_16 "The configuration EEPROM failed to load or save the module configuration.";
CM_ SG_ 2416410627 Phase_U_16 "Phase current is the MOSFET loop current, in the branch U of the converter.";
CM_ SG_ 2416410627 Phase_V_16 "Phase current is the MOSFET loop current, in the branch V of the converter.";
CM_ SG_ 2416410627 Phase_W_16 "Phase current is the MOSFET loop current, in the branch W of the converter.";
CM_ SG_ 2416410640 Bus_current_16 "DC Bus current is possitive when current goes from input to output";
CM_ SG_ 2416410638 Phase_U_16 "Phase current is the MOSFET loop current, in the branch U of the converter.";
CM_ SG_ 2416410638 Phase_V_16 "Phase current is the MOSFET loop current, in the branch V of the converter.";
CM_ SG_ 2416410638 Phase_W_16 "Phase current is the MOSFET loop current, in the branch W of the converter.";
CM_ SG_ 2416410638 Stack_position_16 "Sender Stack position";
CM_ SG_ 2416410638 Group_ID_16 "Sender Group ID";
CM_ SG_ 2416410635 Phase_U_16 "RMS Phase current is the MOSFET loop current, in the branch U of the converter.";
CM_ SG_ 2416410635 Phase_V_16 "RMS Phase current is the MOSFET loop current, in the branch V of the converter.";
CM_ SG_ 2416410635 Phase_W_16 "RMS Phase current is the MOSFET loop current, in the branch W of the converter.";
CM_ SG_ 2416410636 Frequency_16 "Frequency of Three-Phase system";
CM_ SG_ 2416410636 Phase_16 "Phase of Three-Phase system";
CM_ SG_ 2416410629 Temp_Bridge_16 "Temperature of the MOSFET block";
CM_ SG_ 2416410629 Temp_Inductors_16 "Temperature of the inductors";
CM_ SG_ 2416410632 Phase_U_16 "The actual PWM duty cycle setpoint";
CM_ SG_ 2416410632 Phase_V_16 "The actual PWM duty cycle setpoint";
CM_ SG_ 2416410632 Phase_W_16 "The actual PWM duty cycle setpoint";
CM_ SG_ 2416410633 Current_setpoint_16 "The actual current setpoint";
CM_ SG_ 2416410633 Voltage_setpoint_16 "The actual voltage setpoint";
CM_ SG_ 2416410633 Frequency_setpoint_16 "The actual frequency setpoint";
CM_ SG_ 2416377952 Keep_Alive_Enable_16 "If set to 1, module will expect to receive this message every second repeatedly, or it will stop operation";
CM_ SG_ 2416377920 Converter_ON_16 "Enable the converter.";
CM_ SG_ 2416377920 PWM_ON_16 "Enable the PWM control mode.";
CM_ SG_ 2416377920 DC_Current_feedback_ON_16 "Enable the DC current loop";
CM_ SG_ 2416377920 AC_Current_feedback_ON_16 "Enable the AC current loop";
CM_ SG_ 2416377920 Buck_ON_16 "Enable the buck control mode.";
CM_ SG_ 2416377920 Boost_ON_16 "Enable the boost control mode.";
CM_ SG_ 2416377920 Rectifier_3ph_ON_16 "Enable the three-phase rectifier control mode.";
CM_ SG_ 2416377920 Inverter_1ph_ON_16 "Enable the single-phase inverter control mode.";
CM_ SG_ 2416377920 Rectifier_1ph_ON_16 "Enable the single-phase rectifier control mode.";
CM_ SG_ 2416377920 Boost_Neutral_ON_16 "Enable the boost control mode with neutral generation.";
CM_ SG_ 2416377920 Inverter_3ph_ON_16 "Enable the three-phase inverter control mode.";
CM_ SG_ 2416377920 Inverter_1ph_Sync_ON_16 "Single-phase inverter control mode with phase synchronization.";
CM_ SG_ 2416377920 Neutral_ON_16 "Open-loop neutral generation.";
CM_ SG_ 2416377920 Rectifier_1ph_Buck_ON_16 "Single-phase rectifier with buck on one leg.";
CM_ SG_ 2416377920 Inverter_1ph_Boost_ON_16 "Single-phase inverter with boost on one leg.";
CM_ SG_ 2416377920 Rectifier_Distributed_ON_16 "Single-phase (floating) distributed rectifier";
CM_ SG_ 2416377920 MPPT_buck_ON_16 "MPPT buck";
CM_ SG_ 2416377920 MPPT_boost_ON_16 "MPPT boost";
CM_ SG_ 2416377920 Buck_2p_float_ON_16 "Boost on L1 and L2. Floating L3 (high-impedance)";
CM_ SG_ 2416377920 Inverter_1ph_Distributed_ON_16 "Single-phase inverter mode distributed";
CM_ SG_ 2416377936 Clear_Interlock_16 "Clears the converter interlock";
CM_ SG_ 2416377936 Reset_Processor_16 "Reset the converter DSP";
CM_ SG_ 2416377936 Trip_Interlock_16 "Trip the inetrnal Interlock";
CM_ SG_ 2416377921 Reactive_current_setpoint_16 "This defines reactive current setpoint for 3-phase rectifier mode";
CM_ SG_ 2416377922 Phase_U_16 "The actual PWM duty cycle setpoint";
CM_ SG_ 2416377922 Phase_V_16 "The actual PWM duty cycle setpoint";
CM_ SG_ 2416377922 Phase_W_16 "The actual PWM duty cycle setpoint";
CM_ SG_ 2416377923 Current_setpoint_16 "Sets the output current setpoint. Active only when the current loop is enabled";
CM_ SG_ 2416377924 Voltage_setpoint_16 "Sets the output voltage setpoint. Active only when the voltage loop is enabled";
CM_ SG_ 2416377928 Frequency_setpoint_16 "Sets the frequency for single-phase and three-phase generator modes.";
CM_ SG_ 2416377929 Phase_setpoint_16 "Sets the phase for inverter control modes.";
CM_ SG_ 2416377925 Stack_position_16 "The converter position within the stack";
CM_ SG_ 2416377925 Stack_size_16 "How many PFC converters are in stack in total";
CM_ SG_ 2416377925 SN_number_16 "Unique module serial number";
CM_ SG_ 2416377904 Phase_voltage_min_16 "Minimum tolerated phase voltage";
CM_ SG_ 2416377904 Phase_voltage_max_16 "Maximum allowable phase voltage";
CM_ SG_ 2416377904 DC_voltage_min_16 "Minimum allowable dc voltage";
CM_ SG_ 2416377904 DC_voltage_max_16 "Maximum allowable dc voltage";
CM_ SG_ 2416377905 Phase_current_min_16 "Minimum allowable output current";
CM_ SG_ 2416377905 Phase_current_max_16 "Maximum allowable output current";
CM_ SG_ 2416377932 Group_ID_16 "Desired group ID for the device";
CM_ SG_ 2416410639 Group_ID_16 "Group ID of the device";
CM_ SG_ 2416377953 Factory_mode_16 "Customers MUST NOT USE this bit. If set to 1, module will enter in factory mode. ";
CM_ SG_ 2416377953 Silent_CAN_mode_16 "Customers MUST NOT USE this bit. If set to 1, module will enter in factory mode. ";
CM_ SG_ 2416377930 start_16 "Start automatic calibration. Multiplexer index must be 0!";
CM_ SG_ 2416377931 point_16 "Calibration point index.";
CM_ SG_ 2416377926 CRC_16 "Checksum of bytes 0 to 3, CRC-CCITT, corresponding to qChecksum (www.qt.io)";
CM_ SG_ 2416377927 CRC_16 "Checksum of bytes 0 to 3, CRC-CCITT, corresponding to qChecksum (www.qt.io)";
CM_ SG_ 2416410710 Current_U_High_16 "This flag is set if a hight current on U tripped the internal interlock";
CM_ SG_ 2416410710 Current_U_Low_16 "This flag is set if a low current on U tripped the internal interlock";
CM_ SG_ 2416410710 Current_V_High_16 "This flag is set if a hight current on V tripped the internal interlock";
CM_ SG_ 2416410710 Current_V_Low_16 "This flag is set if a low current on V tripped the internal interlock";
CM_ SG_ 2416410710 Current_W_High_16 "This flag is set if a hight current on W tripped the internal interlock";
CM_ SG_ 2416410710 Current_W_Low_16 "This flag is set if a low current on W tripped the internal interlock";
CM_ SG_ 2416410710 Voltage_DC_16 "This flag is set if a voltage on DC tripped the internal interlock";
CM_ SG_ 2416410710 Reboot_16 "This flag is set if a reboot tripped the internal interlock";
CM_ SG_ 2416410710 Unknown_16 "This flag the reason for the internal interlock is unknown";

BA_DEF_ BO_ "SystemMessageLongSymbol" STRING;

BA_ "SystemMessageLongSymbol" BO_ 2416377921 "AFE_Reactive_Current_Setpoint_Control_16";
BA_ "SystemMessageLongSymbol" BO_ 2416377928 "AFE_Frequency_Setpoint_Control_16";
BA_ "SystemMessageLongSymbol" BO_ 2416377968 "AFE_Rectifier_Setpoint_Control_16";
BA_ "SystemMessageLongSymbol" BO_ 2416377926 "_AFE_Calibration_Offset_Update_16";

VAL_ 2416410624 Device_type_16 7 "AFE";
VAL_ 2416410630 Protection_trip_internal_16 1 "fault";
VAL_ 2416410630 Protection_trip_external_16 1 "fault";
VAL_ 2416410630 Phase_U_overcurrent_16 1 "fault";
VAL_ 2416410630 Phase_U_overvoltage_16 1 "fault";
VAL_ 2416410630 Phase_U_undervoltage_16 1 "fault";
VAL_ 2416410630 Phase_V_overvoltage_16 1 "fault";
VAL_ 2416410630 Phase_V_undervoltage_16 1 "fault";
VAL_ 2416410630 Phase_V_overcurrent_16 1 "fault";
VAL_ 2416410630 Phase_W_overvoltage_16 1 "fault";
VAL_ 2416410630 Phase_W_undervoltage_16 1 "fault";
VAL_ 2416410630 Phase_W_overcurrent_16 1 "fault";
VAL_ 2416410630 DC_undervoltage_16 1 "fault";
VAL_ 2416410630 DC_overvoltage_16 1 "fault";
VAL_ 2416410630 MOSFET_overtemperature_16 1 "fault";
VAL_ 2416410630 Inductor_overtemperature_16 1 "fault";
VAL_ 2416410630 Keep_Alive_not_served_16 1 "fault";
VAL_ 2416410630 PLL_not_locked_16 1 "fault";
VAL_ 2416410630 NFO_16 1 "fault";
VAL_ 2416410630 Measurement_system_failure_16 1 "fault";
VAL_ 2416410630 EEPROM_failure_16 1 "fault";
VAL_ 2416410630 System_16 1 "fault";
VAL_ 2416410710 Current_U_High_16 1 "fault";
VAL_ 2416410710 Current_U_Low_16 1 "fault";
VAL_ 2416410710 Current_V_High_16 1 "fault";
VAL_ 2416410710 Current_V_Low_16 1 "fault";
VAL_ 2416410710 Current_W_High_16 1 "fault";
VAL_ 2416410710 Current_W_Low_16 1 "fault";
VAL_ 2416410710 Voltage_DC_16 1 "fault";
VAL_ 2416410710 Reboot_16 1 "fault";
VAL_ 2416410710 Unknown_16 1 "fault";
SIG_VALTYPE_ 2416410705 Current_U_16 : 1;
SIG_VALTYPE_ 2416410705 Current_V_16 : 1;
SIG_VALTYPE_ 2416410705 Current_W_16 : 1;
SIG_VALTYPE_ 2416410705 Voltage_U_16 : 1;
SIG_VALTYPE_ 2416410705 Voltage_V_16 : 1;
SIG_VALTYPE_ 2416410705 Voltage_W_16 : 1;
SIG_VALTYPE_ 2416410705 Voltage_DC_16 : 1;
SIG_VALTYPE_ 2416410706 Current_U_16 : 1;
SIG_VALTYPE_ 2416410706 Current_V_16 : 1;
SIG_VALTYPE_ 2416410706 Current_W_16 : 1;
SIG_VALTYPE_ 2416410706 Voltage_U_16 : 1;
SIG_VALTYPE_ 2416410706 Voltage_V_16 : 1;
SIG_VALTYPE_ 2416410706 Voltage_W_16 : 1;
SIG_VALTYPE_ 2416410706 Voltage_DC_16 : 1;
